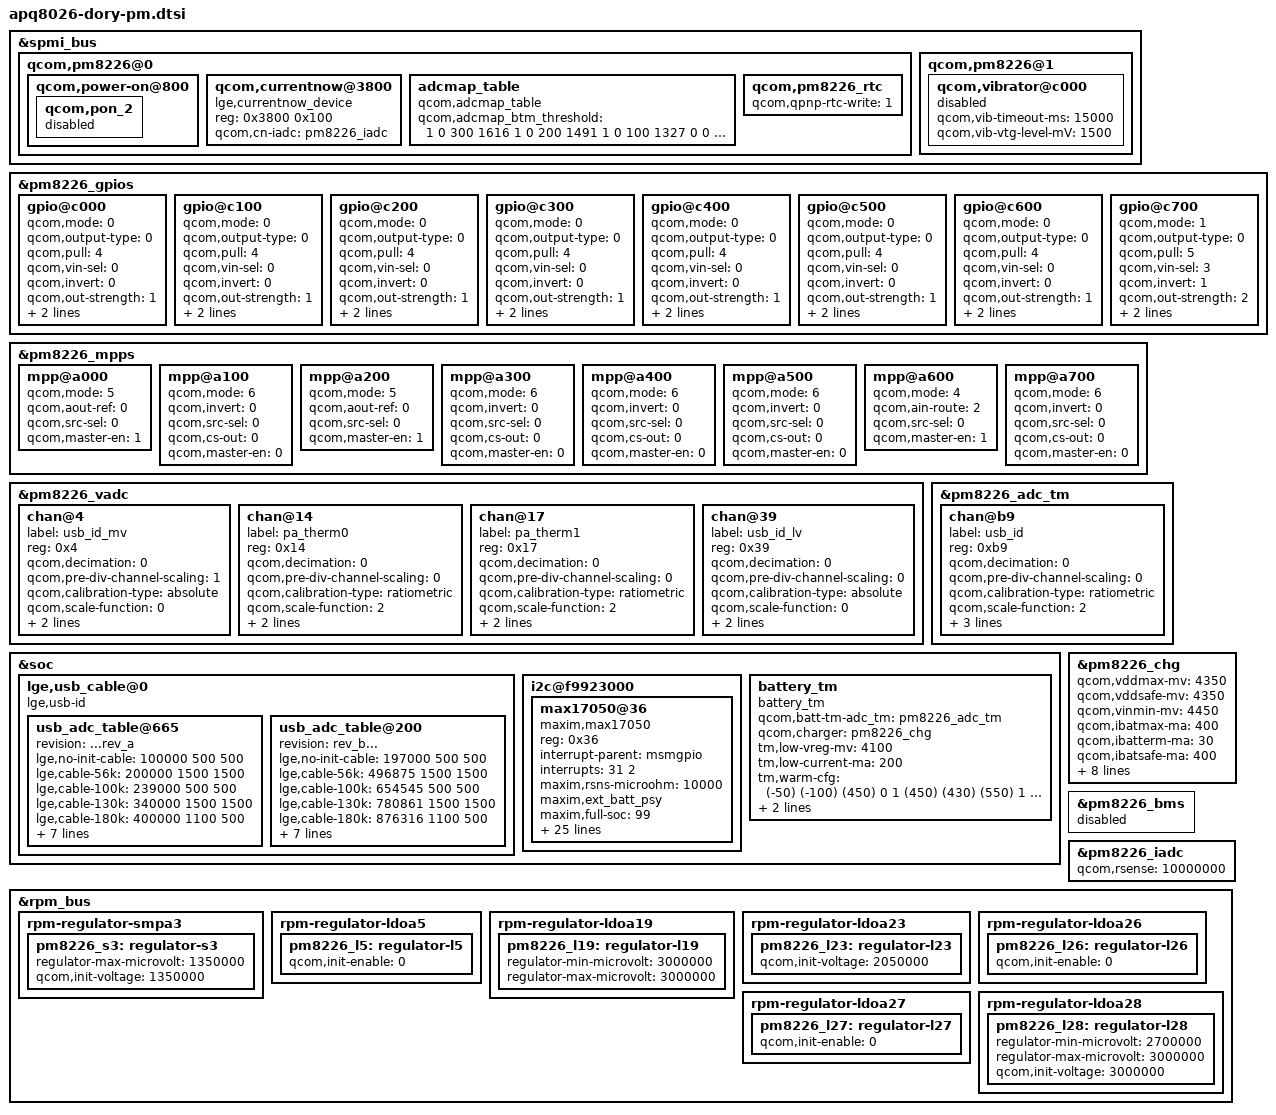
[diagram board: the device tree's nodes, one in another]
/* Copyright (c) 2012, Code Aurora Forum. All rights reserved.
/* Copyright (c) 2013,2014, LGE Inc. All rights reserved.
 *
 * This program is free software; you can redistribute it and/or modify
* it under the terms of the GNU General Public License version 2 and
* only version 2 as published by the Free Software Foundation.
*
* This program is distributed in the hope that it will be useful,
* but WITHOUT ANY WARRANTY; without even the implied warranty of
* MERCHANTABILITY or FITNESS FOR A PARTICULAR PURPOSE.  See the
* GNU General Public License for more details.
*/

&spmi_bus {
	qcom,pm8226@0 {
		qcom,power-on@800 {
			qcom,pon_2 {
				status = "disabled";
			};
		};

		qcom,currentnow@3800 {
			compatible ="lge,currentnow_device";
			reg = <0x3800 0x100>;
			qcom,cn-iadc = <&pm8226_iadc>;
			status = "okay";
		};

		/*
		 * Since negative numbers are not allowed in device trees,
		 * the first two digits here specify if the last two are
		 * negative: 0 == positive, 1 == negative.
		 */
		adcmap_table {
			compatible = "qcom,adcmap_table";
			status = "okay";
			qcom,adcmap_btm_threshold = <
				1 0 300 1616
				1 0 200 1491
				1 0 100 1327
				0 0 0 1140
				0 0 10 1121
				0 0 20 1102
				0 0 30 1083
				0 0 40 1064
				0 0 50 1045
				0 0 60 1026
				0 0 70 1008
				0 0 80 990
				0 0 90 972
				0 0 100 954
				0 0 110 937
				0 0 120 919
				0 0 130 902
				0 0 140 886
				0 0 150 869
				0 0 160 853
				0 0 170 838
				0 0 180 822
				0 0 190 807
				0 0 200 792
				0 0 210 778
				0 0 220 764
				0 0 230 750
				0 0 240 737
				0 0 250 724
				0 0 260 711
				0 0 270 699
				0 0 280 687
				0 0 290 676
				0 0 300 665
				0 0 310 654
				0 0 320 643
				0 0 330 633
				0 0 340 623
				0 0 350 614
				0 0 360 604
				0 0 370 595
				0 0 380 587
				0 0 390 578
				0 0 400 570
				0 0 410 562
				0 0 420 555
				0 0 430 548
				0 0 440 541
				0 0 450 534
				0 0 460 527
				0 0 470 521
				0 0 480 515
				0 0 490 509
				0 0 500 503
				0 0 510 498
				0 0 520 493
				0 0 530 488
				0 0 540 483
				0 0 550 478
				0 0 560 474
				0 0 570 469
				0 0 580 465
				0 0 590 461
				0 0 600 457
				0 0 610 453
				0 0 620 450
				0 0 630 446
				0 0 640 443
				0 0 650 440
				0 0 660 437
				0 0 670 434
				0 0 680 431
				0 0 690 428
				0 0 700 425
				0 0 710 423
				0 0 720 420
				0 0 730 418
				0 0 740 415
				0 0 750 413
				0 0 760 411
				0 0 770 409
				0 0 780 407
				0 0 790 405>;
		};
		qcom,pm8226_rtc {
			qcom,qpnp-rtc-write = <1>;
		};
	};

	qcom,pm8226@1 {
		qcom,vibrator@c000 {
                        status = "disabled";
                        qcom,vib-timeout-ms = <15000>;
                        qcom,vib-vtg-level-mV = <1500>;
		};
	};
};

&pm8226_gpios {
	gpio@c000 { /* GPIO 1 */		/* NOT USED CONFIG */
		qcom,mode = <0>;		/* QPNP_PIN_MODE_DIG_IN */
		qcom,output-type = <0>;		/* QPNP_PIN_OUT_BUF_CMOS */
		qcom,pull = <4>;		/* QPNP_PIN_PULL_DN */
		qcom,vin-sel = <0>;		/* QPNP_PIN_VIN0 */
		qcom,invert = <0>;		/* QPNP_PIN_INVERT_DISABLE */
		qcom,out-strength = <1>;	/* QPNP_PIN_OUT_STRENGTH_LOW */
		qcom,src-sel = <0>;		/* QPNP_PIN_SEL_FUNC_CONSTANT */
		qcom,master-en = <0>;		/* Disable GPIO */
	};

	gpio@c100 { /* GPIO 2 */		/* NOT USED CONFIG */
		qcom,mode = <0>;		/* QPNP_PIN_MODE_DIG_IN */
		qcom,output-type = <0>;		/* QPNP_PIN_OUT_BUF_CMOS */
		qcom,pull = <4>;		/* QPNP_PIN_PULL_DN */
		qcom,vin-sel = <0>;		/* QPNP_PIN_VIN0 */
		qcom,invert = <0>;		/* QPNP_PIN_INVERT_DISABLE */
		qcom,out-strength = <1>;	/* QPNP_PIN_OUT_STRENGTH_LOW */
		qcom,src-sel = <0>;		/* QPNP_PIN_SEL_FUNC_CONSTANT */
		qcom,master-en = <0>;		/* Disable GPIO */
	};

	gpio@c200 { /* GPIO 3 */		/* NOT USED CONFIG */
		qcom,mode = <0>;		/* QPNP_PIN_MODE_DIG_IN */
		qcom,output-type = <0>;		/* QPNP_PIN_OUT_BUF_CMOS */
		qcom,pull = <4>;		/* QPNP_PIN_PULL_DN */
		qcom,vin-sel = <0>;		/* QPNP_PIN_VIN0 */
		qcom,invert = <0>;		/* QPNP_PIN_INVERT_DISABLE */
		qcom,out-strength = <1>;	/* QPNP_PIN_OUT_STRENGTH_LOW */
		qcom,src-sel = <0>;		/* QPNP_PIN_SEL_FUNC_CONSTANT */
		qcom,master-en = <0>;		/* Disable GPIO */
	};

	gpio@c300 { /* GPIO 4 */		/* NOT USED CONFIG */
		qcom,mode = <0>;		/* QPNP_PIN_MODE_DIG_IN */
		qcom,output-type = <0>;		/* QPNP_PIN_OUT_BUF_CMOS */
		qcom,pull = <4>;		/* QPNP_PIN_PULL_DN */
		qcom,vin-sel = <0>;		/* QPNP_PIN_VIN0 */
		qcom,invert = <0>;		/* QPNP_PIN_INVERT_DISABLE */
		qcom,out-strength = <1>;	/* QPNP_PIN_OUT_STRENGTH_LOW */
		qcom,src-sel = <0>;		/* QPNP_PIN_SEL_FUNC_CONSTANT */
		qcom,master-en = <0>;		/* Disable GPIO */
	};

	gpio@c400 { /* GPIO 5 */		/* NOT USED CONFIG */
		qcom,mode = <0>;		/* QPNP_PIN_MODE_DIG_IN */
		qcom,output-type = <0>;		/* QPNP_PIN_OUT_BUF_CMOS */
		qcom,pull = <4>;		/* QPNP_PIN_PULL_DN */
		qcom,vin-sel = <0>;		/* QPNP_PIN_VIN0 */
		qcom,invert = <0>;		/* QPNP_PIN_INVERT_DISABLE */
		qcom,out-strength = <1>;	/* QPNP_PIN_OUT_STRENGTH_LOW */
		qcom,src-sel = <0>;		/* QPNP_PIN_SEL_FUNC_CONSTANT */
		qcom,master-en = <0>;		/* Disable GPIO */
	};

	gpio@c500 { /* GPIO 6 */		/* NOT USED CONFIG */
		qcom,mode = <0>;		/* QPNP_PIN_MODE_DIG_IN */
		qcom,output-type = <0>;		/* QPNP_PIN_OUT_BUF_CMOS */
		qcom,pull = <4>;		/* QPNP_PIN_PULL_DN */
		qcom,vin-sel = <0>;		/* QPNP_PIN_VIN0 */
		qcom,invert = <0>;		/* QPNP_PIN_INVERT_DISABLE */
		qcom,out-strength = <1>;	/* QPNP_PIN_OUT_STRENGTH_LOW */
		qcom,src-sel = <0>;		/* QPNP_PIN_SEL_FUNC_CONSTANT */
		qcom,master-en = <0>;		/* Disable GPIO */
	};

	gpio@c600 { /* GPIO 7 */		/* NOT USED CONFIG */
		qcom,mode = <0>;		/* QPNP_PIN_MODE_DIG_IN */
		qcom,output-type = <0>;		/* QPNP_PIN_OUT_BUF_CMOS */
		qcom,pull = <4>;		/* QPNP_PIN_PULL_DN */
		qcom,vin-sel = <0>;		/* QPNP_PIN_VIN0 */
		qcom,invert = <0>;		/* QPNP_PIN_INVERT_DISABLE */
		qcom,out-strength = <1>;	/* QPNP_PIN_OUT_STRENGTH_LOW */
		qcom,src-sel = <0>;		/* QPNP_PIN_SEL_FUNC_CONSTANT */
		qcom,master-en = <0>;		/* Disable GPIO */
	};

	gpio@c700 { /* GPIO 8 */		/* BOOST_BYP_BYP */
		qcom,mode = <1>;		/* QPNP_PIN_MODE_DIG_OUT */
		qcom,output-type = <0>;		/* QPNP_PIN_OUT_BUF_CMOS */
		qcom,pull = <5>;		/* QPNP_PIN_PULL_NO */
		qcom,vin-sel = <3>;		/* QPNP_PIN_VIN2 */
		qcom,invert = <1>;		/* QPNP_PIN_INVERT_ENABLE */
		qcom,out-strength = <2>;	/* QPNP_PIN_OUT_STRENGTH_MED */
		qcom,src-sel = <0>;		/* QPNP_PIN_SEL_FUNC_CONSTANT */
		qcom,master-en = <1>;		/* Enable GPIO */
	};
};

&pm8226_mpps {
	mpp@a000 { /* MPP 1 */			/* VREF_MSM_PX */
		qcom,mode = <5>;		/* QPNP_PIN_MODE_AOUT */
		qcom,aout-ref = <0>;		/* QPNP_PIN_AOUT_1V25 - Not Fixed */
		qcom,src-sel = <0>;		/* QPNP_PIN_SEL_FUNC_CONSTANT - QCT TBD */
		qcom,master-en = <1>;		/* Enable MPP */
	};

	mpp@a100 { /* MPP 2 */			/* NOT USED CONFIG */
		qcom,mode = <6>;		/* QPNP_PIN_MODE_SINK */
		qcom,invert = <0>;		/* QPNP_PIN_INVERT_DISABLE */
		qcom,src-sel = <0>;		/* QPNP_PIN_SEL_FUNC_CONSTANT - QCT TBD */
		qcom,cs-out = <0>;		/* QPNP_PIN_CS_OUT_5MA */
		qcom,master-en = <0>;		/* DISABLE MPP */
	};

	mpp@a200 { /* MPP 3 */			/* VREF_LDO */
		qcom,mode = <5>;		/* QPNP_PIN_MODE_AOUT */
		qcom,aout-ref = <0>;		/* QPNP_PIN_AOUT_1V25 */
		qcom,src-sel = <0>;		/* QPNP_PIN_SEL_FUNC_CONSTANT - QCT TBD */
		qcom,master-en = <1>;		/* Enable MPP */
	};

	mpp@a300 { /* MPP 4 */			/* NOT USED CONFIG */
		qcom,mode = <6>;		/* QPNP_PIN_MODE_SINK */
		qcom,invert = <0>;		/* QPNP_PIN_INVERT_DISABLE */
		qcom,src-sel = <0>;		/* QPNP_PIN_SEL_FUNC_CONSTANT - QCT TBD */
		qcom,cs-out = <0>;		/* QPNP_PIN_CS_OUT_5MA */
		qcom,master-en = <0>;		/* DISABLE MPP */
	};

	mpp@a400 { /* MPP 5 */			/* NOT USED CONFIG */
		qcom,mode = <6>;		/* QPNP_PIN_MODE_SINK */
		qcom,invert = <0>;		/* QPNP_PIN_INVERT_DISABLE */
		qcom,src-sel = <0>;		/* QPNP_PIN_SEL_FUNC_CONSTANT - QCT TBD */
		qcom,cs-out = <0>;		/* QPNP_PIN_CS_OUT_5MA */
		qcom,master-en = <0>;		/* DISABLE MPP */
	};

	mpp@a500 { /* MPP 6 */			/* NOT USED CONFIG */
		qcom,mode = <6>;		/* QPNP_PIN_MODE_SINK */
		qcom,invert = <0>;		/* QPNP_PIN_INVERT_DISABLE */
		qcom,src-sel = <0>;		/* QPNP_PIN_SEL_FUNC_CONSTANT - QCT TBD */
		qcom,cs-out = <0>;		/* QPNP_PIN_CS_OUT_5MA */
		qcom,master-en = <0>;		/* DISABLE MPP */
	};

	mpp@a600 { /* MPP 7 */			/* BOARD_ID */
		qcom,mode = <4>;		/* AIN input */
		qcom,ain-route = <2>;		/* QPNP_PIN_AIN_AMUX_CH7 */
		qcom,src-sel = <0>;		/* QPNP_PIN_SEL_FUNC_CONSTANT */
		qcom,master-en = <1>;		/* Enable MPP */
	};

	mpp@a700 { /* MPP 8 */			/* NOT USED CONFIG */
		qcom,mode = <6>;		/* QPNP_PIN_MODE_SINK */
		qcom,invert = <0>;		/* QPNP_PIN_INVERT_DISABLE */
		qcom,src-sel = <0>;		/* QPNP_PIN_SEL_FUNC_CONSTANT - QCT TBD */
		qcom,cs-out = <0>;		/* QPNP_PIN_CS_OUT_5MA */
		qcom,master-en = <0>;		/* DISABLE MPP */
	};
};

&pm8226_vadc {
	chan@4 {
		label = "usb_id_mv";
		reg = <0x4>;
		qcom,decimation = <0>;
		qcom,pre-div-channel-scaling = <1>;
		qcom,calibration-type = "absolute";
		qcom,scale-function = <0>;
		qcom,hw-settle-time = <0>;
		qcom,fast-avg-setup = <0>;
	};

	chan@14 {
		label = "pa_therm0";
		reg = <0x14>;
		qcom,decimation = <0>;
		qcom,pre-div-channel-scaling = <0>;
		qcom,calibration-type = "ratiometric";
		qcom,scale-function = <2>;
		qcom,hw-settle-time = <2>;
		qcom,fast-avg-setup = <0>;
	};

	chan@17 {
		label = "pa_therm1";
		reg = <0x17>;
		qcom,decimation = <0>;
		qcom,pre-div-channel-scaling = <0>;
		qcom,calibration-type = "ratiometric";
		qcom,scale-function = <2>;
		qcom,hw-settle-time = <2>;
		qcom,fast-avg-setup = <0>;
	};

	chan@39 {
		label = "usb_id_lv";
		reg = <0x39>;
		qcom,decimation = <0>;
		qcom,pre-div-channel-scaling = <0>;
		qcom,calibration-type = "absolute";
		qcom,scale-function = <0>;
		qcom,hw-settle-time = <0>;
		qcom,fast-avg-setup = <0>;
	};

};

&pm8226_adc_tm {
	chan@b9 {
		label = "usb_id";
		reg = <0xb9>;
		qcom,decimation = <0>;
		qcom,pre-div-channel-scaling = <0>;
		qcom,calibration-type = "ratiometric";
		qcom,scale-function = <2>;
		qcom,hw-settle-time = <2>;
		qcom,fast-avg-setup = <3>;
		qcom,btm-channel-number = <0x88>;
	};
};

&soc {
	/* Cable type definition.
	* Modify the USB cable and move to SoC
	* to get each table for different USB Pull up resistor via HW Rev
	* This must have the compatible property "lge,usb-id".
	* If you don't want to use revision you can remove status & revision property.
	* If this node is not exist, the charger driver would not be probed.
	* Each cable type has 3 values
	* that we can configure the threshold of ADC value and TA/USB IUSB max current value.
	* ex)
	*    cable type = <adc_threshold, TA_MA, USB_MA>.
	*/

	lge,usb_cable@0 {
		compatible = "lge,usb-id";
		usb_adc_table@665{
			status = "okay";
			revision = "...rev_a";
			lge,no-init-cable = <100000 500 500>;
			lge,cable-56k = <200000 1500 1500>;
			lge,cable-100k = <239000 500 500>;
			lge,cable-130k = <340000 1500 1500>;
			lge,cable-180k = <400000 1100 500>;
			lge,cable-200k = <430000 1100 500>;
			lge,cable-220k = <485000 1100 500>;
			lge,cable-270k = <560000 1100 500>;
			lge,cable-330k = <735000 500 500>;
			lge,cable-620k = <955000 500 500>;
			lge,cable-910k = <1140000 1500 1500>;
			lge,cable-none = <1900000 1100 500>;
		};

		usb_adc_table@200{
			status = "okay";
			revision = "rev_b...";
			lge,no-init-cable = <197000 500 500>;
			lge,cable-56k = <496875 1500 1500>;
			lge,cable-100k = <654545 500 500>;
			lge,cable-130k = <780861 1500 1500>;
			lge,cable-180k = <876316 1100 500>;
			lge,cable-200k = <921429 1100 500>;
			lge,cable-220k = <988450 1100 500>;
			lge,cable-270k = <1077399 1100 500>;
			lge,cable-330k = <1240865 500 500>;
			lge,cable-620k = <1418326 500 500>;
			lge,cable-910k = <1637838 1500 1500>;
			lge,cable-none = <1900000 1100 500>;
		};
	};

	i2c@f9923000 {
		max17050@36 {
			compatible = "maxim,max17050";
			reg = <0x36>;
			interrupt-parent = <&msmgpio>;
			interrupts = <31 2>;

			maxim,rsns-microohm = <10000>;
			maxim,ext_batt_psy;
			maxim,full-soc = <99>;
			maxim,empty-soc = <0>;

			maxim,model = [A0 50 AA C0 AD 80 B4 10
					B5 00 B7 B0 B8 20 B8 90
					BC 30 BC 80 C3 40 C3 90
					CB 40 CC 80 D6 D0 D7 90
					00 C0 01 70 01 D0 04 40
					08 E0 2D B0 09 20 0C 20
					0C C0 11 20 0C C0 08 50
					06 60 06 90 0A A0 0A A0
					01 00 01 00 01 00 01 00
					01 00 01 00 01 00 01 00
					01 00 01 00 01 00 01 00
					01 00 01 00 01 00 01 00];

			maxim,relaxcfg = <0x506B>;
			maxim,config = <0x2100>;
			maxim,filtercfg = <0x87A4>;
			maxim,learncfg = <0x2606>;
			maxim,misccfg = <0x0870>;
			maxim,fullsocthr = <0x5F00>;
			maxim,rcomp0 = <0x004F>;
			maxim,tempco = <0x2F35>;
			maxim,tempnom = <0x1400>;
			maxim,tgain = <0xE932>;
			maxim,toff = <0x2381>;
			maxim,ichgterm = <0x00C0>;
			maxim,vempty = <0x964C>;
			maxim,qrtable00 = <0x0D84>;
			maxim,qrtable10 = <0x0A08>;
			maxim,qrtable20 = <0x0884>;
			maxim,qrtable30 = <0x0584>;
			maxim,capacity = <0x0320>;
			maxim,vf_fullcap = <0x0320>;
			maxim,temperature = <0x1400>;
			maxim,dpacc = <0x0C80>;
			maxim,param-version = <0x2>;
		};
	};

	battery_tm {
		compatible = "battery_tm";
		status = "ok";
		qcom,batt-tm-adc_tm = <&pm8226_adc_tm>;
		qcom,charger = <&pm8226_chg>;
		tm,low-vreg-mv = <4100>;
		tm,low-current-ma = <200>;
		tm,warm-cfg = <
			 (-50) (-100) (450) 0 1
			 (450)  (430) (550) 1 2
			 (550)  (430) (600) 2 2
			 (600)  (430) (790) 3 2>;
		tm,cool-cfg = <
			(-100) (-300) (-50) 2 7
			 (430) (-100) (450) 0 1>;
	};
};

&pm8226_chg {
	qcom,vddmax-mv = <4350>;
	qcom,vddsafe-mv = <4350>;
	qcom,vinmin-mv = <4450>;
	qcom,ibatmax-ma= <400>;
	qcom,ibatterm-ma = <30>;
	qcom,ibatsafe-ma = <400>;
	qcom,vbatdet-delta-mv = <100>;
	qcom,tchg-mins = <480>;
	qcom,thermal-mitigation = <0>; /* disable */
	qcom,btc-disabled;
	qcom,warm-bat-decidegc = <0>; /* disable */
	qcom,cool-bat-decidegc = <0>; /* disable */
	qcom,step-dwn-offset-ma = <200>;
	qcom,step-dwn-thr-mv = <4250>;
};

&pm8226_bms{
	status = "disabled";
};

&pm8226_iadc {
       qcom,rsense = <10000000>;
};

&rpm_bus {
	rpm-regulator-smpa3 {
		status = "okay";
		pm8226_s3: regulator-s3 {
			regulator-max-microvolt = <1350000>;
			qcom,init-voltage = <1350000>;
			status = "okay";
		};
	};
	rpm-regulator-ldoa5 {
		status = "okay";
		pm8226_l5: regulator-l5 {
			qcom,init-enable = <0>;
			status = "okay";
		};
	};
	rpm-regulator-ldoa19 {
		status = "okay";
		pm8226_l19: regulator-l19 {
			regulator-min-microvolt = <3000000>;
			regulator-max-microvolt = <3000000>;
			status = "okay";
		};
	};
	/* admp441 i2s microphone */
	rpm-regulator-ldoa23 {
		pm8226_l23: regulator-l23 {
			qcom,init-voltage = <2050000>;
		};
	};
	rpm-regulator-ldoa26 {
		status = "okay";
		pm8226_l26: regulator-l26 {
			qcom,init-enable = <0>;
			status = "okay";
		};
	};
	rpm-regulator-ldoa27 {
		status = "okay";
		pm8226_l27: regulator-l27 {
			qcom,init-enable = <0>;
			status = "okay";
		};
	};
	rpm-regulator-ldoa28 {
		status = "okay";
		pm8226_l28: regulator-l28 {
			regulator-min-microvolt = <2700000>;
			regulator-max-microvolt = <3000000>;
			qcom,init-voltage = <3000000>;
			status = "okay";
		};
	};
};
